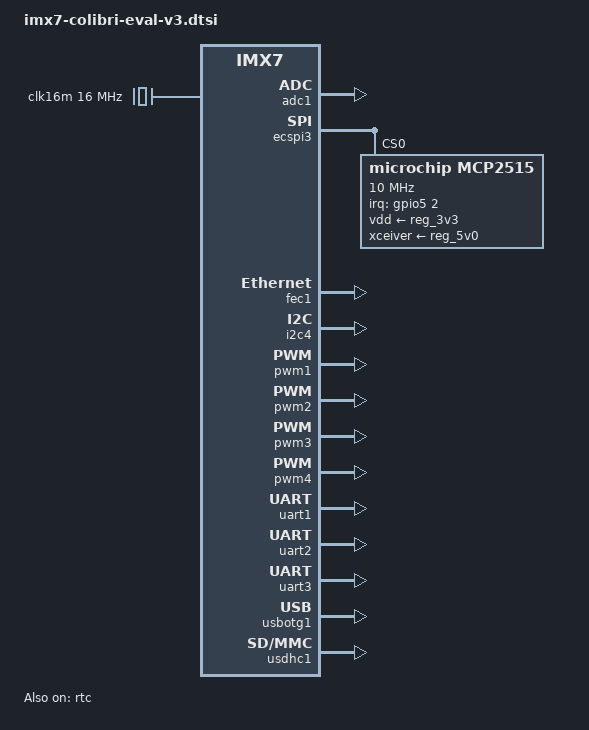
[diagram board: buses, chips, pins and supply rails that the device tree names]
/ {
	clk16m: clk16m {
		compatible = "fixed-clock";
		#clock-cells = <0>;
		clock-frequency = <16000000>;
	};
};
&adc1 {
	status = "okay";
};
&atmel_mxt_ts {
	interrupt-parent = <&gpio1>;
	interrupts = <9 IRQ_TYPE_EDGE_FALLING>;		 
	pinctrl-0 = <&pinctrl_atmel_adapter>;
	reset-gpios = <&gpio1 10 GPIO_ACTIVE_LOW>;	 
	status = "disabled";
};
&ecspi3 {
	status = "okay";
	mcp2515: can@0 {
		clocks = <&clk16m>;
		compatible = "microchip,mcp2515";
		interrupt-parent = <&gpio5>;
		interrupts = <2 IRQ_TYPE_EDGE_FALLING>;
		pinctrl-names = "default";
		pinctrl-0 = <&pinctrl_can_int>;
		reg = <0>;
		spi-max-frequency = <10000000>;
		vdd-supply = <&reg_3v3>;
		xceiver-supply = <&reg_5v0>;
	};
};
&fec1 {
	status = "okay";
};
&i2c4 {
	status = "okay";
};
&pwm1 {
	status = "okay";
};
&pwm2 {
	status = "okay";
};
&pwm3 {
	status = "okay";
};
&pwm4 {
	status = "okay";
};
&rtc {
	status = "okay";
};
&uart1 {
	status = "okay";
};
&uart2 {
	status = "okay";
};
&uart3 {
	status = "okay";
};
&usbotg1 {
	disable-over-current;
	status = "okay";
};
&usdhc1 {
	status = "okay";
};
